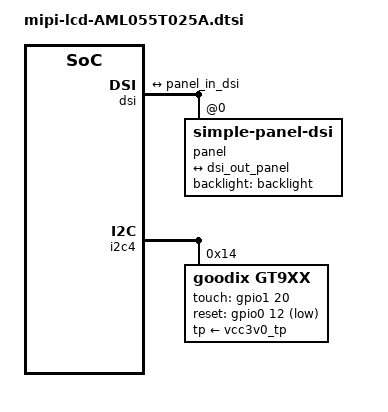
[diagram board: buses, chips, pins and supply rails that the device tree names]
/*
 * Copyright (c) 2022 Biandenhuo Co., Ltd
 */

&dsi {
	//rockchip,lane-rate = <420>;     // 62MHz(Pixel Clock) * 3(Pixel Clock Divider) * 2 (Double Data Rate) = 372Mbps
	status = "okay";

	panel@0 {
		compatible = "simple-panel-dsi";
		reg = <0>;
		backlight = <&backlight>;

		/*reset-gpios = <&gpio4 29 GPIO_ACTIVE_LOW>;*/      /*GPIO4_D5*/
		/*enable-gpios = <&gpio4 22 GPIO_ACTIVE_HIGH>;*/     /*GPIO4_C6*/

		prepare-delay-ms = <20>;
		reset-delay-ms = <20>;
		init-delay-ms = <20>;
		enable-delay-ms = <20>;
		disable-delay-ms = <20>;
		unprepare-delay-ms = <20>;
		
		dsi,flags = <(MIPI_DSI_MODE_VIDEO | MIPI_DSI_MODE_VIDEO_BURST)>;
		dsi,format = <MIPI_DSI_FMT_RGB888>;
		dsi,lanes = <4>;

		/*AML055T025A HX8394F-720P*/
        	//is3587; /* use dev_read_bool(dsi->dev, "is3587") to detect */
				//Normal
				//39 00 07 B2 00 80 64 0C 0D 2F
				//BIST
				//39 00 0C B2 00 80 64 0C 0D 2F 00 00 00 00 38
		panel-init-sequence = [
				39 00 04 B9 FF 83 94
				39 00 07 BA 63 03 68 6B B2 C0
				39 00 0B B1 48 12 72 09 32 54 71 71 57 47
				39 00 07 B2 00 80 64 0C 0D 2F
				39 00 16 B4 73 74 73 74 73 74 01 0C 86 75 00 3F 73 74 73 74 73 74 01 0C 86
				39 00 22 D3 00 00 07 07 40 07 0C 00 08 10 08 00 08 54 15 0A 05 0A 02 15 06 05 06 47 44 0A 0A 4B 10 07 07 0C 40
				39 00 2D D5 1C 1C 1D 1D 00 01 02 03 04 05 06 07 08 09 0A 0B 24 25 18 18 26 27 18 18 18 18 18 18 18 18 18 18 18 18 18 18 18 18 20 21 18 18 18 18
				39 00 2D D6 1C 1C 1D 1D 07 06 05 04 03 02 01 00 0B 0A 09 08 21 20 18 18 27 26 18 18 18 18 18 18 18 18 18 18 18 18 18 18 18 18 25 24 18 18 18 18
				39 00 03 B6 92 92
				39 00 3B E0 00 0A 15 1B 1E 21 24 22 47 56 65 66 6E 82 88 8B 9A 9D 98 A8 B9 5D 5C 61 66 6A 6F 7F 7F 00 0A 15 1B 1E 21 24 22 47 56 65 65 6E 81 87 8B 98 9D 99 A8 BA 5D 5D 62 67 6B 72 7F 7F
				39 00 03 C0 1F 31
				15 00 02 CC 0B
				15 00 02 D4 02
				15 00 02 BD 02
				39 00 0D D8 FF FF FF FF FF FF FF FF FF FF FF FF
				15 00 02 BD 00
				15 00 02 BD 01
				15 00 02 B1 00
				15 00 02 BD 00
				39 00 08 BF 40 81 50 00 1A FC 01
				15 00 02 C6 ED
				15 00 02 35 00
				05 78 01 11
				05 32 01 29
		];

		display-timings {
			native-mode = <&timing0>;
			timing0: timing0 {
				clock-frequency = <68000000>;
				hactive = <720>;
				vactive = <1280>;

				hsync-len = <50>;
				hback-porch = <50>;
				hfront-porch = <50>;

				vsync-len = <4>;
				vback-porch = <4>;
				vfront-porch = <10>;

				hsync-active = <0>;
				vsync-active = <0>;
				de-active = <0>;
				pixelclk-active = <0>;
			};
		};		

		ports {
			#address-cells = <1>;
			#size-cells = <0>;
			
			port@0 {
			        reg = <0>;
			        panel_in_dsi: endpoint {
			                remote-endpoint = <&dsi_out_panel>;
			        };
			};
		};

	};

	ports {
		#address-cells = <1>;
		#size-cells = <0>;
		port@1 {
			reg = <1>;
			dsi_out_panel: endpoint {
				remote-endpoint = <&panel_in_dsi>;
			};
		};
	};

};

&i2c4 {
	gt9xx: gt9xx@14 {
		compatible = "goodix,gt9xx";
		reg = <0x14>;
		//touch-gpio = <&gpio4 28 IRQ_TYPE_LEVEL_LOW>; /*GPIO4_D4 TE on LCD*/
		touch-gpio = <&gpio1 20 IRQ_TYPE_LEVEL_LOW>; /*GPIO1_C4*/
		reset-gpio = <&gpio0 12 GPIO_ACTIVE_LOW>; /*GPIO0_B4*/
                pinctrl-names = "default";
                pinctrl-0 = <&touch_io>;
		max-x = <720>;
		max-y = <1280>;
		tp-size = <911>;
		tp-supply = <&vcc3v0_tp>;
	};
};
